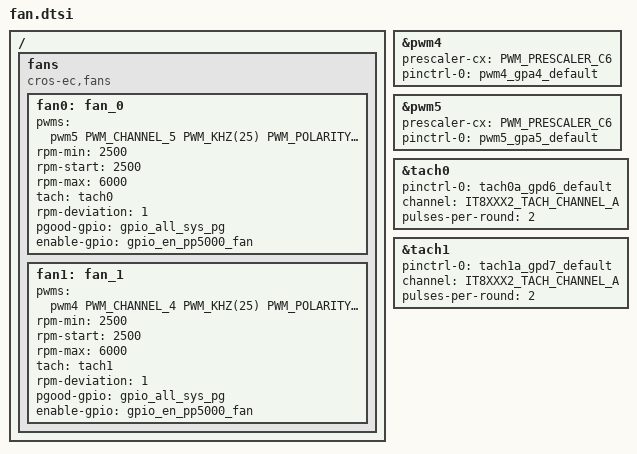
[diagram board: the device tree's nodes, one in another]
/* Copyright 2026 The ChromiumOS Authors
 * Use of this source code is governed by a BSD-style license that can be
 * found in the LICENSE file.
 */
/ {
	fans {
		compatible = "cros-ec,fans";

		fan0: fan_0 {
			pwms = <&pwm5 PWM_CHANNEL_5 PWM_KHZ(25) PWM_POLARITY_NORMAL>;
			rpm-min = <2500>;
			rpm-start = <2500>;
			rpm-max = <6000>;
			tach = <&tach0>;
			rpm-deviation = <1>;
			pgood-gpio = <&gpio_all_sys_pg>;
			enable-gpio = <&gpio_en_pp5000_fan>;
		};
		fan1: fan_1 {
			pwms = <&pwm4 PWM_CHANNEL_4 PWM_KHZ(25) PWM_POLARITY_NORMAL>;
			rpm-min = <2500>;
			rpm-start = <2500>;
			rpm-max = <6000>;
			tach = <&tach1>;
			rpm-deviation = <1>;
			pgood-gpio = <&gpio_all_sys_pg>;
			enable-gpio = <&gpio_en_pp5000_fan>;
		};
	};
};

&pwm4 {
	status = "okay";
	prescaler-cx = <PWM_PRESCALER_C6>;
	pinctrl-0 = <&pwm4_gpa4_default>;
	pinctrl-names = "default";
};

&pwm5 {
	status = "okay";
	prescaler-cx = <PWM_PRESCALER_C6>;
	pinctrl-0 = <&pwm5_gpa5_default>;
	pinctrl-names = "default";
};

&tach0 {
	status = "okay";
	pinctrl-0 = <&tach0a_gpd6_default>;
	pinctrl-names = "default";
	channel = <IT8XXX2_TACH_CHANNEL_A>;
	pulses-per-round = <2>;
};

&tach1 {
	status = "okay";
	pinctrl-0 = <&tach1a_gpd7_default>;
	pinctrl-names = "default";
	channel = <IT8XXX2_TACH_CHANNEL_A>;
	pulses-per-round = <2>;
};
